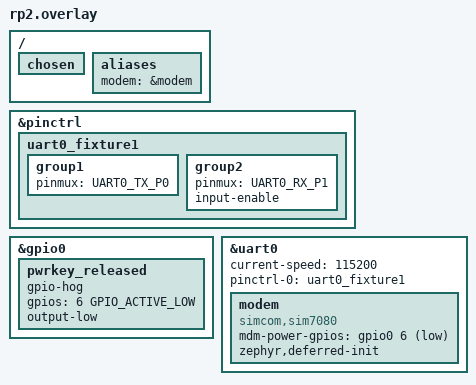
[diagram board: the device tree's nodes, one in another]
/* SPDX-License-Identifier: Apache-2.0 OR MIT */

#include <zephyr/dt-bindings/pinctrl/rpi-pico-rp2350a-pinctrl.h>

/ {
	chosen {
		/delete-property/ zephyr,console;
		/delete-property/ zephyr,shell-uart;
	};

	aliases {
		modem = &modem;
	};
};

&pinctrl {
	uart0_fixture1: uart0_fixture1 {
		group1 {
			pinmux = <UART0_TX_P0>;
		};
		group2 {
			pinmux = <UART0_RX_P1>;
			input-enable;
		};
	};
};

/*
 * PWRKEY is driven released from the start. The driver configures the pin
 * only in its init, which this image defers, and the RP2350 resets a pad
 * with its pull-down on, which the harness's input, without a pull of
 * its own, reads as low: low for 500 ms is a power-on press.
 */
&gpio0 {
	pwrkey_released {
		gpio-hog;
		gpios = <6 GPIO_ACTIVE_LOW>;
		output-low;
	};
};

/*
 * The fixture's crossed pair: the DUT's GP0 drives the harness's GP1 and
 * the harness's GP0 drives the DUT's GP1.
 */
&uart0 {
	status = "okay";
	current-speed = <115200>;
	pinctrl-0 = <&uart0_fixture1>;
	pinctrl-names = "default";

	/*
	 * Deferred: the driver's init boots the modem and brings PDP up
	 * synchronously, retrying for about 30 s without a modem. The rig flashes
	 * and pings the DUT before a case attaches the model, so the case runs
	 * the init with `MODEM INIT` instead.
	 */
	modem: modem {
		compatible = "simcom,sim7080";
		mdm-power-gpios = <&gpio0 6 GPIO_ACTIVE_LOW>;
		zephyr,deferred-init;
		status = "okay";
	};
};
